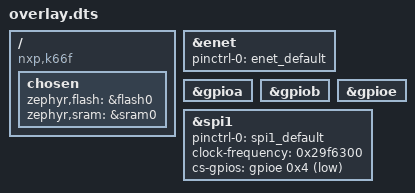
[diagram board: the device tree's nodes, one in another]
/ {
	compatible = "nxp,k66f", "nxp,k6x", "nxp,mk66f18";
	chosen {
		zephyr,flash = &flash0;
		zephyr,sram = &sram0;
	};
};
&enet{
	status = "okay";
	pinctrl-0 = < &enet_default >;
	pinctrl-names = "default";
};
&gpioa{
	status = "okay";
};
&gpiob{
	status = "okay";
};
&gpioe{
	status = "okay";
};
&spi1{
	status = "okay";
	pinctrl-0 = < &spi1_default >;
	pinctrl-names = "default";
	clock-frequency = < 0x29f6300 >;
	cs-gpios = < &gpioe 0x4 0x1 >;
};
